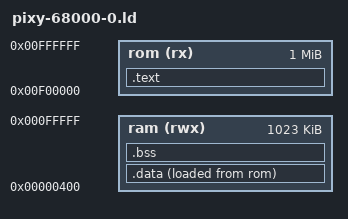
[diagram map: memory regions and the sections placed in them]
STARTUP(crt0.o)
OUTPUT_FORMAT("elf32-m68k")
OUTPUT_ARCH(m68k)
ENTRY(_start)

SEARCH_DIR("/home/kouji/.m68k-elf-gcc/m68k-elf/lib");
GROUP(-lc)
INPUT(pixy-68000-0.o)
__DYNAMIC = 0;

MEMORY
{
  ram (rwx)  : ORIGIN = 0x000400, LENGTH = 1M - 0x000400
  rom (rx)   : ORIGIN = 0xf00000, LENGTH = 1M
}

PROVIDE (__stack = 0);
PROVIDE (software_init_hook = 0);
PROVIDE (_software_init_hook = 0);

SECTIONS
{
  .text :
  {
    __init_vec = .;
    LONG(ORIGIN(ram) + LENGTH(ram));
    LONG(_start);
    *(.vector)

    . = ALIGN(0x400);
    CREATE_OBJECT_SYMBOLS
    *(.text .text.*)

    . = ALIGN(0x4);
    /* These are for running static constructors and destructors under ELF.  */
    KEEP (*crtbegin.o(.ctors))
    KEEP (*(EXCLUDE_FILE (*crtend.o) .ctors))
    KEEP (*(SORT(.ctors.*)))
    KEEP (*(.ctors))
    KEEP (*crtbegin.o(.dtors))
    KEEP (*(EXCLUDE_FILE (*crtend.o) .dtors))
    KEEP (*(SORT(.dtors.*)))
    KEEP (*(.dtors))

    *(.rodata .rodata.*)

    . = ALIGN(0x4);
    *(.gcc_except_table) 

    . = ALIGN(0x4);
    *(.eh_frame)

    . = ALIGN(0x4);
    __INIT_SECTION__ = . ;
    LONG (0x4e560000)	/* linkw %fp,#0 */
    *(.init)
    SHORT (0x4e5e)	/* unlk %fp */
    SHORT (0x4e75)	/* rts */

    . = ALIGN(0x4);
    __FINI_SECTION__ = . ;
    LONG (0x4e560000)	/* linkw %fp,#0 */
    *(.fini)
    SHORT (0x4e5e)	/* unlk %fp */
    SHORT (0x4e75)	/* rts */

    _etext = .;
    *(.lit)
  } > rom

  .data :
  {
    *(.got.plt) *(.got)
    *(.shdata)
    *(.data .data.*)
    _edata = .;
  } > ram AT > rom

  .bss :
  {
    . = ALIGN(0x4);
    __bss_start = . ;
    *(.shbss)
    *(.bss .bss.*)
    *(COMMON)
    _end =  ALIGN (0x8);
    __end = _end;
  } > ram

  .stab 0 (NOLOAD) :
  {
    *(.stab)
  }

  .stabstr 0 (NOLOAD) :
  {
    *(.stabstr)
  }
}
